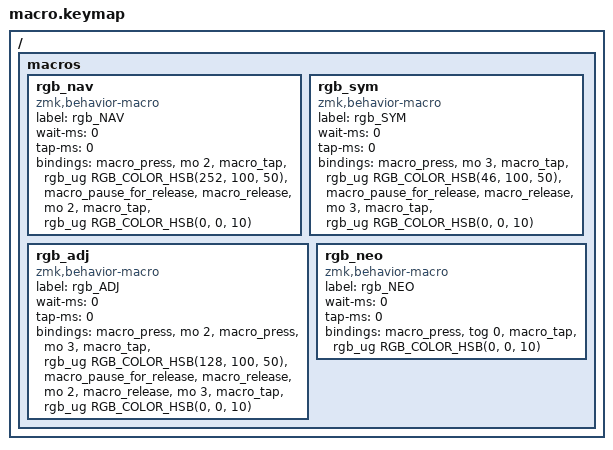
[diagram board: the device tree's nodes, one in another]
/ {
    macros {
        rgb_nav: rgb_nav {
            label = "rgb_NAV";
            compatible = "zmk,behavior-macro";
            #binding-cells = <0>;
            wait-ms = <0>;
            tap-ms = <0>;
            bindings
                = <&macro_press &mo 2>
                , <&macro_tap &rgb_ug RGB_COLOR_HSB(252, 100, 50)> // Blue
                , <&macro_pause_for_release>
                , <&macro_release &mo 2>
                , <&macro_tap &rgb_ug RGB_COLOR_HSB(0, 0, 10)>;
        };
        rgb_sym: rgb_sym {
            label = "rgb_SYM";
            compatible = "zmk,behavior-macro";
            #binding-cells = <0>;
            wait-ms = <0>;
            tap-ms = <0>;
            bindings
                = <&macro_press &mo 3>
                , <&macro_tap &rgb_ug RGB_COLOR_HSB(46, 100, 50)> // Yellow
                , <&macro_pause_for_release>
                , <&macro_release &mo 3>
                , <&macro_tap &rgb_ug RGB_COLOR_HSB(0, 0, 10)>;
        };
        rgb_adj: rgb_adj {
            label = "rgb_ADJ";
            compatible = "zmk,behavior-macro";
            #binding-cells = <0>;
            wait-ms = <0>;
            tap-ms = <0>;
            bindings
                = <&macro_press &mo 2>
                , <&macro_press &mo 3>
                , <&macro_tap &rgb_ug RGB_COLOR_HSB(128, 100, 50)> // Green
                , <&macro_pause_for_release>
                , <&macro_release &mo 2>
                , <&macro_release &mo 3>
                , <&macro_tap &rgb_ug RGB_COLOR_HSB(0, 0, 10)>;
        };
        rgb_neo: rgb_neo {
            label = "rgb_NEO";
            compatible = "zmk,behavior-macro";
            #binding-cells = <0>;
            wait-ms = <0>;
            tap-ms = <0>;
            bindings
                = <&macro_press &tog 0>
                , <&macro_tap &rgb_ug RGB_COLOR_HSB(0, 0, 10)>; // White
        };
    };
};
